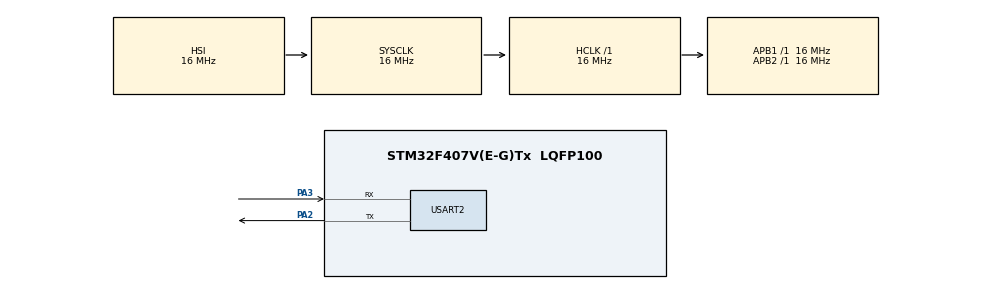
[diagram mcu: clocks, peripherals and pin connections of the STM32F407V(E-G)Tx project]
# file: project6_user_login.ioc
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Mcu.Family=STM32F4
Mcu.Name=STM32F407V(E-G)Tx
Mcu.Package=LQFP100
NVIC.PriorityGroup=NVIC_PRIORITYGROUP_4
NVIC.USART2_IRQn=true\:0\:0\:false\:false\:true\:true\:true\:true
PA13.Mode=Serial_Wire
PA13.Signal=SYS_JTMS-SWDIO
PA14.Mode=Serial_Wire
PA14.Signal=SYS_JTCK-SWCLK
PA2.Mode=Asynchronous
PA2.Signal=USART2_TX
PA3.Mode=Asynchronous
PA3.Signal=USART2_RX
ProjectManager.HeapSize=0x200
ProjectManager.StackSize=0x400
ProjectManager.TargetToolchain=STM32CubeIDE
RCC.AHBFreq_Value=16000000
RCC.APB1Freq_Value=16000000
RCC.APB2Freq_Value=16000000
RCC.CortexFreq_Value=16000000
RCC.HSE_VALUE=25000000
RCC.HSI_VALUE=16000000
RCC.LSE_VALUE=32768
RCC.SYSCLKFreq_VALUE=16000000
RCC.VCOOutputFreq_Value=192000000
USART2.VirtualMode=VM_ASYNC
board=custom

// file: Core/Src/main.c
/* USER CODE BEGIN Header */
/**
  ******************************************************************************
  * @file           : main.c
  * @brief          : Main program body
  ******************************************************************************
  * @attention
  *
  * Copyright (c) 2024 STMicroelectronics.
  * All rights reserved.
  *
  * This software is licensed under terms that can be found in the LICENSE file
  * in the root directory of this software component.
  * If no LICENSE file comes with this software, it is provided AS-IS.
  *
  ******************************************************************************
  */
/* USER CODE END Header */
#include "main.h"

/* USER CODE BEGIN Includes */
#include "string.h"

/* USER CODE END Includes */

UART_HandleTypeDef huart2;

/* USER CODE BEGIN PV */
unsigned char rx_data[1] = {0};
uint8_t counter = 0 ;
unsigned char data[20] = {0};
uint8_t counter_ = 0;
uint8_t counter__ = 0;
unsigned char tx_data[] = "\nEnter the surname:";
unsigned char tx_data_[] = "\nEnter the password:";
unsigned char tx_data__[] = "Press any key:";

unsigned char data_rx1[20] = {0};
unsigned char data_rx2[20] = {0};
/* USER CODE END PV */

void SystemClock_Config(void);
static void MX_GPIO_Init(void);
static void MX_USART2_UART_Init(void);

/* USER CODE BEGIN 0 */
void HAL_UART_RxCpltCallback(UART_HandleTypeDef *huart)
{
	data[counter] = rx_data[0];
	counter++;
	if((counter_ == 0) & (counter__ == 0))
	{
		counter_ = 0;
		counter__ = 1;
	}
	else if((counter_ == 1) & (counter__ == 1))
	{
		counter_ = 1;
		counter__ = 2;
	}
	else if((counter_ == 2) & (counter__ == 2))
	{
		counter_ = 2;
		counter__ = 3;
	}

	HAL_UART_Receive_IT(&huart2, (uint8_t*)rx_data, sizeof(rx_data));
}

/* USER CODE END 0 */

int main(void)
{

  /* MCU Configuration--------------------------------------------------------*/

  /* Reset of all peripherals, Initializes the Flash interface and the Systick. */
  HAL_Init();

  /* Configure the system clock */
  SystemClock_Config();

  /* Initialize all configured peripherals */
  MX_GPIO_Init();
  MX_USART2_UART_Init();
  /* USER CODE BEGIN 2 */
  HAL_UART_Receive_IT(&huart2, (uint8_t *)rx_data, sizeof(rx_data));
  HAL_UART_Transmit(&huart2, tx_data__, strlen((char*)tx_data__), HAL_MAX_DELAY);

  /* USER CODE END 2 */
  /* Infinite loop */
  while (1)
  {

    /* USER CODE BEGIN 3 */

	  if((counter_ == 0 ) & (counter__ == 1))
	  {
		  HAL_UART_Transmit(&huart2, tx_data, strlen((char*)tx_data), HAL_MAX_DELAY);
		  counter_ = 1;
	  }
	  else if((counter_ == 1 ) & (counter__ == 2))
	  {
		  // Copy the data
		  for(int i = 0; i < counter; i++)
		  {
			  data_rx1[i] = data[i];
		  }
		  //strcpy((char*)data_rx1, (char*)data);

		  // Transmit the data
		  HAL_UART_Transmit(&huart2, tx_data_, strlen((char*)tx_data_), HAL_MAX_DELAY);
		  counter_ = 2;
	  }
	  else if((counter_ == 2 ) & (counter__ == 3))
	  {
		  // Copy the data
		  	for(int i = 0; i < counter; i++)
		  	{
		  		data_rx2[i] = data[i];
		  	}
		    // strcpy((char*)data_rx2, (char*)data);

		    if (strcmp((const char*)data_rx1, "SezaiGuler") == 0 && strcmp((const char*)data_rx2, "1234567890") == 0) // username and password control
			{
				  HAL_UART_Transmit(&huart2, (uint8_t *)"\nWell Done", 10, HAL_MAX_DELAY);
				  HAL_UART_Transmit(&huart2, (uint8_t*)tx_data_, sizeof(tx_data_), HAL_MAX_DELAY);
				  counter_ = 1;
				  counter__ = 1;
			}
			else
			{
				  HAL_UART_Transmit(&huart2, (uint8_t *)"\nThe Password is incorrect", 26, HAL_MAX_DELAY);
				  HAL_UART_Transmit(&huart2, (uint8_t*)tx_data, sizeof(tx_data), HAL_MAX_DELAY);
				  counter_ = 1;
				  counter__ = 1;
			}
	  }
	  HAL_Delay(2);
	  counter = 0;
  }
  /* USER CODE END 3 */
}

void SystemClock_Config(void)
{
  RCC_OscInitTypeDef RCC_OscInitStruct = {0};
  RCC_ClkInitTypeDef RCC_ClkInitStruct = {0};

  /** Configure the main internal regulator output voltage
  */
  __HAL_RCC_PWR_CLK_ENABLE();
  __HAL_PWR_VOLTAGESCALING_CONFIG(PWR_REGULATOR_VOLTAGE_SCALE1);

  /** Initializes the RCC Oscillators according to the specified parameters
  * in the RCC_OscInitTypeDef structure.
  */
  RCC_OscInitStruct.OscillatorType = RCC_OSCILLATORTYPE_HSI;
  RCC_OscInitStruct.HSIState = RCC_HSI_ON;
  RCC_OscInitStruct.HSICalibrationValue = RCC_HSICALIBRATION_DEFAULT;
  RCC_OscInitStruct.PLL.PLLState = RCC_PLL_NONE;
  if (HAL_RCC_OscConfig(&RCC_OscInitStruct) != HAL_OK)
  {
    Error_Handler();
  }

  /** Initializes the CPU, AHB and APB buses clocks
  */
  RCC_ClkInitStruct.ClockType = RCC_CLOCKTYPE_HCLK|RCC_CLOCKTYPE_SYSCLK
                              |RCC_CLOCKTYPE_PCLK1|RCC_CLOCKTYPE_PCLK2;
  RCC_ClkInitStruct.SYSCLKSource = RCC_SYSCLKSOURCE_HSI;
  RCC_ClkInitStruct.AHBCLKDivider = RCC_SYSCLK_DIV1;
  RCC_ClkInitStruct.APB1CLKDivider = RCC_HCLK_DIV1;
  RCC_ClkInitStruct.APB2CLKDivider = RCC_HCLK_DIV1;

  if (HAL_RCC_ClockConfig(&RCC_ClkInitStruct, FLASH_LATENCY_0) != HAL_OK)
  {
    Error_Handler();
  }
}

static void MX_USART2_UART_Init(void)
{

  huart2.Instance = USART2;
  huart2.Init.BaudRate = 115200;
  huart2.Init.WordLength = UART_WORDLENGTH_8B;
  huart2.Init.StopBits = UART_STOPBITS_1;
  huart2.Init.Parity = UART_PARITY_NONE;
  huart2.Init.Mode = UART_MODE_TX_RX;
  huart2.Init.HwFlowCtl = UART_HWCONTROL_NONE;
  huart2.Init.OverSampling = UART_OVERSAMPLING_16;
  if (HAL_UART_Init(&huart2) != HAL_OK)
  {
    Error_Handler();
  }

}

static void MX_GPIO_Init(void)
{

  /* GPIO Ports Clock Enable */
  __HAL_RCC_GPIOA_CLK_ENABLE();

}

void Error_Handler(void)
{
  __disable_irq();
  while (1)
  {
  }
}
